# psram2kx32e_PSRAM2KX32E_RAM_41888000h register map
Vendor: Texas Instruments
Peripheral module from a debugger description file (folder AM275x).
Registers are 32-bit, read-write, reset 0x0 unless marked. A register's access mark holds for its fields unless they carry their own. Offsets are as the file gives them; lines under a group give offsets from that group; [hi:lo] are bit positions; {n}, {i} and the like mark numbered series; 'fields as' and 'values as' point back to an identical list; <NAME> marks a mode.

## psram2kx32e_RAM
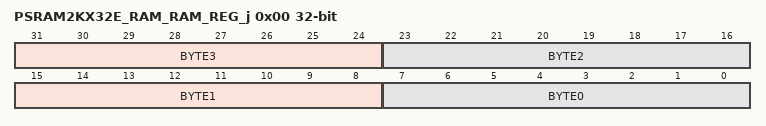
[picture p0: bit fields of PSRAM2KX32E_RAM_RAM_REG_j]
0x00 PSRAM2KX32E_RAM_RAM_REG_j — The RAM memory words provide memory mapped random access data storage.
  [31:24] BYTE3 — This is the MS byte Reset Source: rst_mod_g_rst_n
  [23:16] BYTE2 — This is the UM byte Reset Source: rst_mod_g_rst_n
  [15:8] BYTE1 — This is the LM byte Reset Source: rst_mod_g_rst_n
  [7:0] BYTE0 — This is the LS byte Reset Source: rst_mod_g_rst_n
